# N32G41x register map
Vendor: Nsingtech Ltd.; File version: 1.0
CPU: CM4 r0p1, little endian, no MPU, no FPU, 4 interrupt priority bits
Registers are 32-bit, read-write, reset 0x0 unless marked. A register's access mark holds for its fields unless they carry their own. Offsets are from the block's base; [hi:lo] are bit positions; lines under a group give offsets from that group; {n}, {i} and the like mark numbered series.

## ADC1 — Analog-to-digital converter
Base 0x40020800
Same registers: ADC2 0x40020900
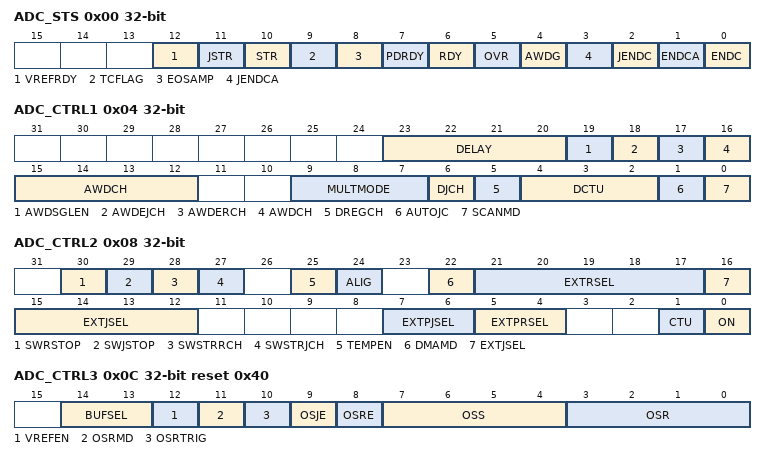
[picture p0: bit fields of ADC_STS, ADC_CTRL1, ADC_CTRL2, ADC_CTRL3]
0x00 ADC_STS — ADC Status Register
  [12] VREFRDY ro — Internal input buffer ready status flag
  [11] JSTR — Inject channel start flag
  [10] STR — Regular channel start flag
  [9] TCFLAG — Turncate flag after oversampling
  [8] EOSAMP — Regular channel sample end flag
  [7] PDRDY — Power down ready
  [6] RDY — ADC ready
  [5] OVR — ADC overrun flag
  [4] AWDG — Analog watchdog flag
  [3] JENDCA — Any injected channel end of conversion
  [2] JENDC — Injected channel end of conversion
  [1] ENDCA — Any regular channel end of conversion
  [0] ENDC — End of conversion
0x04 ADC_CTRL1 — ADC Control Register 1
  [23:20] DELAY — Delay between two sampling phases
  [19] AWDSGLEN — Enable watchdog on a single channel in scan mode
  [18] AWDEJCH — Analog watchdog enable on injected channels
  [17] AWDERCH — Analog watchdog enable on regular channels
  [16:12] AWDCH — Analog watchdog channel select bits
  [9:7] MULTMODE — Multi ADC mode selection
  [6] DJCH — Discontinuous mode on injected channels
  [5] DREGCH — Discontinuous mode on regular channels
  [4:2] DCTU — Discontinuous mode channel count
  [1] AUTOJC — Automatic injected group conversion
  [0] SCANMD — Scan mode
0x08 ADC_CTRL2 — ADC Control Register 2
  [30] SWRSTOP wo — Stop conversion of regular channels
  [29] SWJSTOP wo — Stop conversion of injected channels
  [28] SWSTRRCH wo — Start conversion of regular channels
  [27] SWSTRJCH wo — Start conversion of injected channels
  [25] TEMPEN — Temperature sensor enable
  [24] ALIG — Data alignment
  [22] DMAMD — DMA mode
  [21:17] EXTRSEL — External event select for regular group
  [16:12] EXTJSEL — External event select for injected group
  [7:6] EXTPJSEL — External trigger polarity selection for injected channels
  [5:4] EXTPRSEL — External trigger polarity selection for regular channels
  [1] CTU — Continuous conversion
  [0] ON — A/D converter ON/OFF
0x0C ADC_CTRL3 reset 0x40 — ADC Control Register 3
  [14:13] BUFSEL — VREFP mode selection
  [12] VREFEN — VREFINT enable
  [11] OSRMD — Regular channels oversample mode
  [10] OSRTRIG — Regular channels oversample trigger
  [9] OSJE — Injected channels oversample enable
  [8] OSRE — Regular channels oversample enable
  [7:4] OSS — Oversample data right shift bit width
  [3:0] OSR — Oversample rate configuration
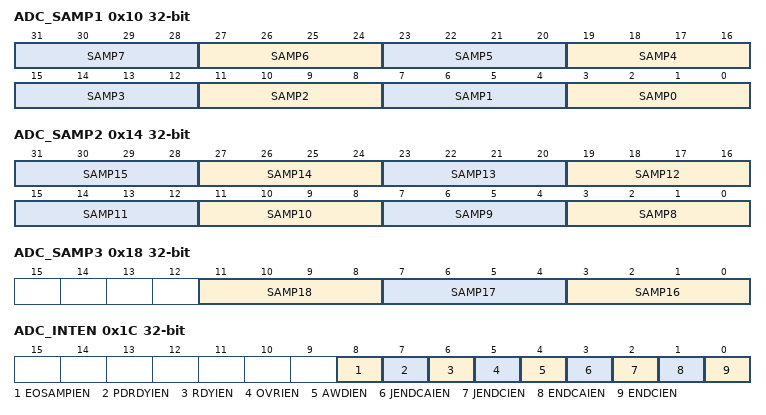
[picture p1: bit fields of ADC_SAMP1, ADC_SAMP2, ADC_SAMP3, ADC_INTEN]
0x10 ADC_SAMP1 — ADC Sample Time Register 1
  [4n+3:4n] SAMP{n} (n=0..7) — Channel {n} sampling time selection
0x14 ADC_SAMP2 — ADC Sample Time Register 2
  [4n-29:4n-32] SAMP{n} (n=8..15) — Channel {n} sampling time selection
0x18 ADC_SAMP3 — ADC Sample Time Register 3
  [11:8] SAMP18 — Channel 18 sampling time selection
  [7:4] SAMP17 — Channel 17 sampling time selection
  [3:0] SAMP16 — Channel 16 sampling time selection
0x1C ADC_INTEN — ADC Interrupt Enable Register
  [8] EOSAMPIEN — ADC sample done interrupt enable
  [7] PDRDYIEN — Power down ready interrupt enable
  [6] RDYIEN — Ready interrupt enable
  [5] OVRIEN — ADC overrun interrupt enable
  [4] AWDIEN — Analog watchdog interrupt enable
  [3] JENDCAIEN — Interrupt enable for any injected channel
  [2] JENDCIEN — Interrupt enable for injected channels
  [1] ENDCAIEN — Interrupt enable for any regular channel
  [0] ENDCIEN — Interrupt enable for ENDC
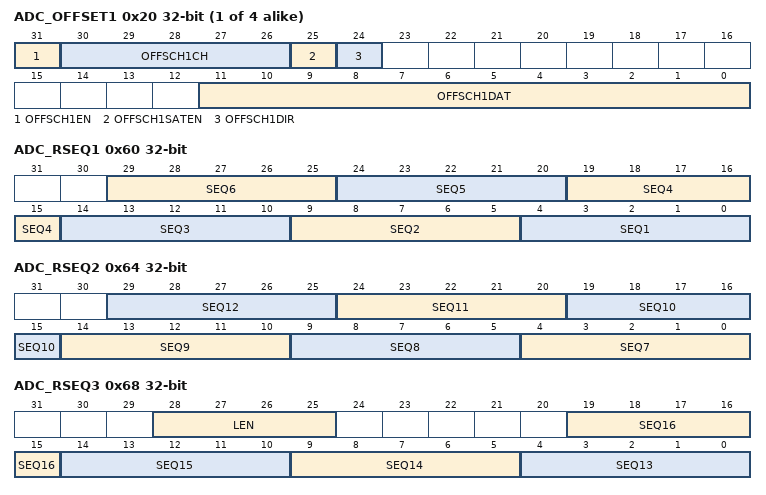
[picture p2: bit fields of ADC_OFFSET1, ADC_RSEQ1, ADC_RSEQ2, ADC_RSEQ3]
{0x1C+4i} ADC_OFFSET{i} (i=1..4) — ADC Data Offset Register {i}
  [31] OFFSCH{i}EN — Offset channel {i} enable
  [30:26] OFFSCH{i}CH — Offset channel {i} selection
  [25] OFFSCH{i}SATEN — Saturation enable
  [24] OFFSCH{i}DIR — Offset direction
  [11:0] OFFSCH{i}DAT — Data offset for channel {i}
0x30 ADC_AWDHIGH reset 0xFFF — ADC Watchdog High Threshold Register
  [11:0] HTH — Analog watchdog high threshold
0x34 ADC_AWDLOW — ADC Watchdog Low Threshold Register
  [11:0] LTH — Analog watchdog low threshold
0x60 ADC_RSEQ1 — ADC Regular Sequence Register 1
  [29:25] SEQ6 — 6th conversion in regular sequence
  [24:20] SEQ5 — 5th conversion in regular sequence
  [19:15] SEQ4 — 4th conversion in regular sequence
  [14:10] SEQ3 — 3rd conversion in regular sequence
  [9:5] SEQ2 — 2nd conversion in regular sequence
  [4:0] SEQ1 — 1st conversion in regular sequence
0x64 ADC_RSEQ2 — ADC Regular Sequence Register 2
  [5n-31:5n-35] SEQ{n} (n=7..12) — {n}th conversion in regular sequence
0x68 ADC_RSEQ3 — ADC Regular Sequence Register 3
  [28:25] LEN — Regular channel sequence length
  [5n-61:5n-65] SEQ{n} (n=13..16) — {n}th conversion in regular sequence
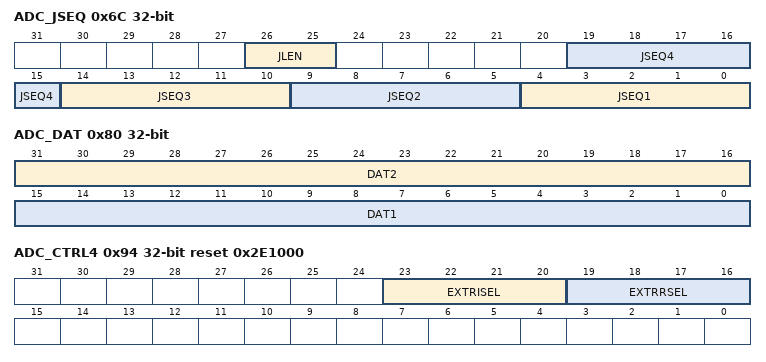
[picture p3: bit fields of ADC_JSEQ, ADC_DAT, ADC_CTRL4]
0x6C ADC_JSEQ — ADC Injected Sequence Register
  [26:25] JLEN — Injected sequence length
  [19:15] JSEQ4 — 4th conversion in injected sequence
  [14:10] JSEQ3 — 3rd conversion in injected sequence
  [9:5] JSEQ2 — 2nd conversion in injected sequence
  [4:0] JSEQ1 — 1st conversion in injected sequence
{0x6C+4i} ADC_JDAT{i} ro (i=1..4) — ADC Injected Data Register {i}
  [15:0] JDAT — Injected data
0x80 ADC_DAT ro — ADC Regular Data Register
  [31:16] DAT2 — 2nd data item of a pair of regular conversions
  [15:0] DAT1 — 1st data item of a pair of regular conversions
0x94 ADC_CTRL4 reset 0x2E1000 — ADC Control Register 4
  [23:20] EXTRISEL — EXTI line selection for injected channel external trigger
  [19:16] EXTRRSEL — EXTI line selection for regular channel external trigger
